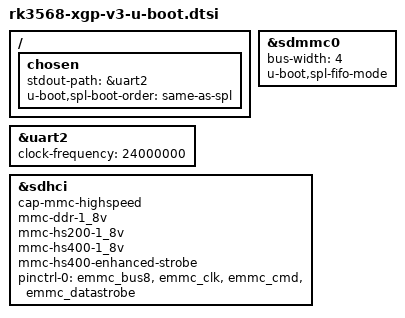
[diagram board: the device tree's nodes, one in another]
// SPDX-License-Identifier: (GPL-2.0+ OR MIT)

#include "rk3568-u-boot.dtsi"

 / {
 	chosen {
 		stdout-path = &uart2;
 		u-boot,spl-boot-order = "same-as-spl", &sdmmc0, &sdhci;
 	};
 };
 
 &sdmmc0 {
 	bus-width = <4>;
 	u-boot,spl-fifo-mode;
 };
 
 &uart2 {
 	u-boot,dm-spl;
 	clock-frequency = <24000000>;
 	status = "okay";
 };

&sdhci {
	cap-mmc-highspeed;
	mmc-ddr-1_8v;
	mmc-hs200-1_8v;
	mmc-hs400-1_8v;
	mmc-hs400-enhanced-strobe;
	pinctrl-0 = <&emmc_bus8 &emmc_clk &emmc_cmd &emmc_datastrobe>;
};
